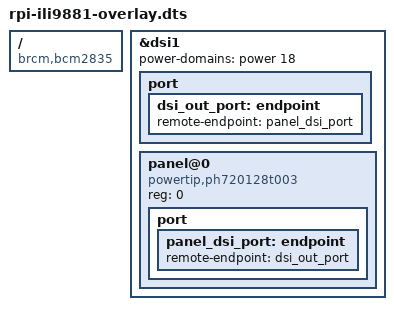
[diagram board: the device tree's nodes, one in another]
/*
 * Device Tree overlay for RaspberryPi PowerTip DSI panel
 *
 */

/dts-v1/;
/plugin/;

/ {
	compatible = "brcm,bcm2835", "brcm,bcm2708", "brcm,bcm2709";

	fragment@0 {
		target = <&dsi1>;
		__overlay__ {
			#address-cells = <1>;
			#size-cells = <0>;
			power-domains = <&power 18>;
			status = "okay";

			port {
				dsi_out_port: endpoint {
					remote-endpoint = <&panel_dsi_port>;
				};
			};

			panel@0 {
				compatible = "powertip,ph720128t003";
				reg = <0>;
				port {
					panel_dsi_port: endpoint {
						remote-endpoint = <&dsi_out_port>;
					};
				};
			};
		};
	};
};
